# AC78xx register map
Vendor: AutoChips; Series: AC78xx; File version: 1.0
CPU: CM3 r2p1, little endian, MPU, no FPU, 3 interrupt priority bits
Registers are 32-bit, read-write, no defined reset value unless marked. A register's access mark holds for its fields unless they carry their own. Offsets are from the block's base; [hi:lo] are bit positions; lines under a group give offsets from that group; {n}, {i} and the like mark numbered series; 'fields as' and 'values as' point back to an identical list.

## ADC — Analog to Digital Convert Module
Base 0x40003000; register names take the prefix ADC_
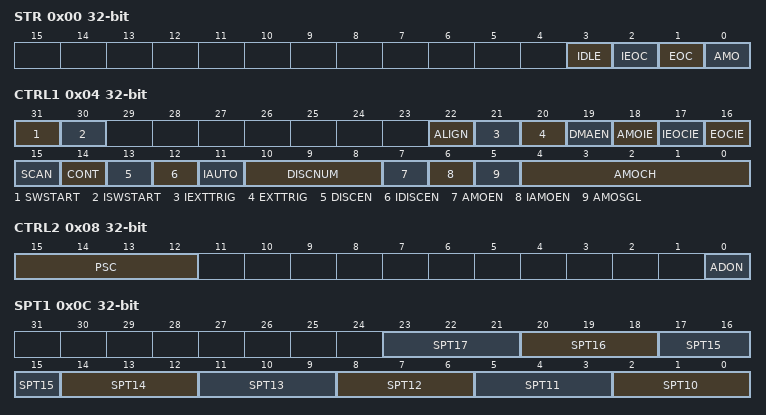
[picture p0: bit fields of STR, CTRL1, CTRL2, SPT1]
0x00 STR — ADC status Register
  [3] IDLE ro — ADC idle state indicate(is useful for sleep function)
    0=ADC not in idle state; 1=ADC is in idle state
  [2] IEOC — Injection group conversion completed flag
    0=Injection group conversion not completed; 1=Injection group conversion completed,write 0 to clear
  [1] EOC — Regular group conversion completed flag
    0=Regular group conversion not completed; 1=Regular group conversion completed,write 0 or Read ADC_RDR to clear
  [0] AMO — Analog monitor event occrs
    0=no analog monitor event; 1=analog monitor event occurs,write 0 to clear
0x04 CTRL1 — ADC control register 1
  [31] SWSTART — software trigger for regular channels
  [30] ISWSTART — software trigger for Inject channels
  [22] ALIGN — Data Alignment
    0=Right Alignment; 1=Left Alignment
  [21] IEXTTRIG — Inject group trig source select
    0=Internal trigger source(software trig); 1=external trigger source
  [20] EXTTRIG — Regular group trig source select
    values as IEXTTRIG
  [19] DMAEN — DMA Function Enable
    0=DMA function Disabled; 1=DMA function Enabled
  [18] AMOIE — AMO interrupt Enable
    0=AMO interrupt Disabled; 1=AMO interrupt Enabled, An interrupt is generated when the AMO bit is set
  [17] IEOCIE — IEOC interrupt Enable
    0=IEOC interrupt Disabled; 1=IEOC interrupt Enabled, An interrupt is generated when the IEOC bit is set
  [16] EOCIE — EOC interrupt Enable
    0=EOC interrupt Disabled; 1=EOC interrupt Enabled, An interrupt is generated when the EOC bit is set
  [15] SCAN — Scan Mode
    0=Scan mode disabled; 1=Scan mode enabled
  [14] CONT — Continuous conversion
    0=Single conversion mode; 1=continuous conversion mode
  [13] DISCEN — Discontinous mode on regular channels
    0=regular group Discontinous mode disabled; 1=regular group Discontinous mode enabled
  [12] IDISCEN — Discontinous mode on injected channels
    0=Injection group Discontinous mode disabled; 1=Injection group Discontinous mode enabled
  [11] IAUTO — Injection Group Automatic conversion
    0=Injection group automatic conversion disabled; 1=Injection group automatic conversion enabled
  [10:8] DISCNUM — Discontinuous conversion length of channel
  [7] AMOEN — Regular Group Analog Monitor Detect function Enable
  [6] IAMOEN — Injection Group Analog Monitor Detect function Enable
  [5] AMOSGL — Analog monitor detecting channel
    0=AMO used in All channels; 1=AMO function used in single channel defined in AMOCH register
  [4:0] AMOCH — Analog monitor detecting channel
0x08 CTRL2 — ADC Control Register 2
  [15:12] PSC — Bus Clock prescaler
  [0] ADON — ADC converter ON/OFF register
    0=Disable ADC conversion and go to power down mode; 1=Enable ADC and to start conversion
0x0C SPT1 — ADC Sample time setting register 1
  [all] fields
    0=6 ADCCLK; 1=14 ADCCLK; 2=29 ADCCLK; 3=42 ADCCLK; 4=56 ADCCLK; 5=72 ADCCLK; 6=215 ADCCLK; 7=3 ADCCLK
  [3n-28:3n-30] SPT{n} (n=10..17) — Sample time for Channel {n}
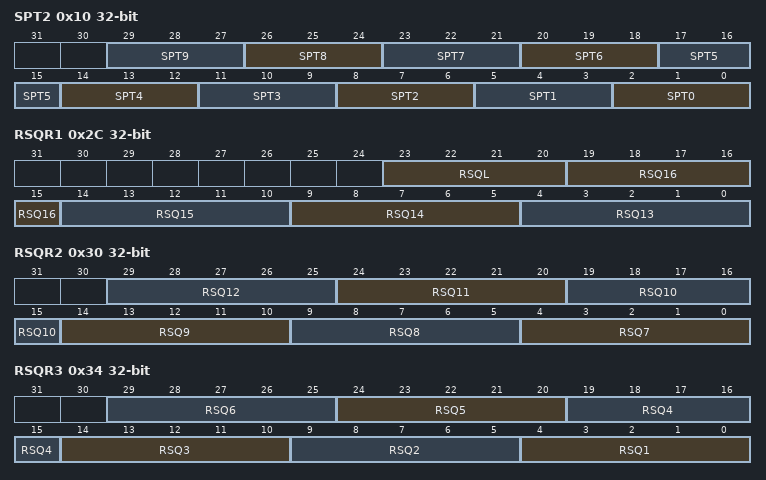
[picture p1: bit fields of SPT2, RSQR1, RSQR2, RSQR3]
0x10 SPT2 — ADC Sample time setting register 2
  [all] fields
    values as the fields of SPT1
  [3n+2:3n] SPT{n} (n=0..9) — Sample time for Channel {n}
{0x10+4i} IOFR{i} (i=1..4) — ADC Injection Group Offset Register(n)
  [11:0] IOFR — Injection group offset Value
0x24 AWDH — AWD High threshold register
  [11:0] AWDH — High threshold value for analog watchdog
0x28 AWDL — AWD Low threshold register
  [11:0] AWDL — Low threshold value for analog watchdog
0x2C RSQR1 — ADC regular group sequence configure register 1
  [23:20] RSQL — length of regular group
  [5n-61:5n-65] RSQ{n} (n=13..16) — channel selection for regular group {n}
0x30 RSQR2 — ADC regular group sequence configure register 2
  [5n-31:5n-35] RSQ{n} (n=7..12) — channel selection for regular group {n}
0x34 RSQR3 — ADC regular group sequence configure register 3
  [5n-1:5n-5] RSQ{n} (n=1..6) — channel selection for regular group {n}
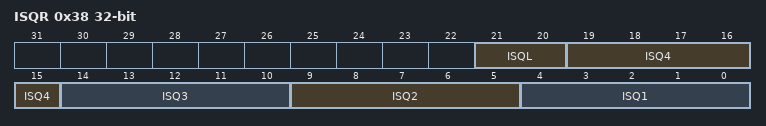
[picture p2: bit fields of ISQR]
0x38 ISQR — ADC injection group sequence configure register
  [21:20] ISQL — length of injection group
  [5n-1:5n-5] ISQ{n} (n=1..4) — channel selection for injection group {n}
{0x38+4i} IDR{i} (i=1..4) ro — ADC Injection Group data Register(n)
  [11:0] IDR — Injection group data Value
0x4C RDR ro — ADC Regular Group data Register
  [11:0] IDR — Regular group data Value

## Notices in the file
Copyright (C) 2012-2014 ARM Limited. All rights reserved.
Purpose: System Viewer Description (SVD) Example (Schema Version 1.1)
This is a description of a none-existent and incomplete device
for demonstration purposes only.
Redistribution and use in source and binary forms, with or without
modification, are permitted provided that the following conditions are met:
- Redistributions of source code must retain the above copyright
notice, this list of conditions and the following disclaimer.
- Redistributions in binary form must reproduce the above copyright
notice, this list of conditions and the following disclaimer in the
documentation and/or other materials provided with the distribution.
- Neither the name of ARM nor the names of its contributors may be used
to endorse or promote products derived from this software without
specific prior written permission.
THIS SOFTWARE IS PROVIDED BY THE COPYRIGHT HOLDERS AND CONTRIBUTORS "AS IS"
AND ANY EXPRESS OR IMPLIED WARRANTIES, INCLUDING, BUT NOT LIMITED TO, THE
IMPLIED WARRANTIES OF MERCHANTABILITY AND FITNESS FOR A PARTICULAR PURPOSE
ARE DISCLAIMED. IN NO EVENT SHALL COPYRIGHT HOLDERS AND CONTRIBUTORS BE
LIABLE FOR ANY DIRECT, INDIRECT, INCIDENTAL, SPECIAL, EXEMPLARY, OR
CONSEQUENTIAL DAMAGES (INCLUDING, BUT NOT LIMITED TO, PROCUREMENT OF
SUBSTITUTE GOODS OR SERVICES; LOSS OF USE, DATA, OR PROFITS; OR BUSINESS
INTERRUPTION) HOWEVER CAUSED AND ON ANY THEORY OF LIABILITY, WHETHER IN
CONTRACT, STRICT LIABILITY, OR TORT (INCLUDING NEGLIGENCE OR OTHERWISE)
ARISING IN ANY WAY OUT OF THE USE OF THIS SOFTWARE, EVEN IF ADVISED OF THE
POSSIBILITY OF SUCH DAMAGE.
